# f28002x_erad_crc_global_regs register map
Vendor: Texas Instruments
Peripheral module from a debugger description file (folder C2000).
Address unit: 16 bits
Registers are 16-bit, read-write, no defined reset value unless marked. A register's access mark holds for its fields unless they carry their own. Offsets are as the file gives them; lines under a group give offsets from that group; [hi:lo] are bit positions; {n}, {i} and the like mark numbered series; 'fields as' and 'values as' point back to an identical list; <NAME> marks a mode.

## ERAD_CRC_GLOBAL_REGS — ERAD CRC GLOBAL Registers
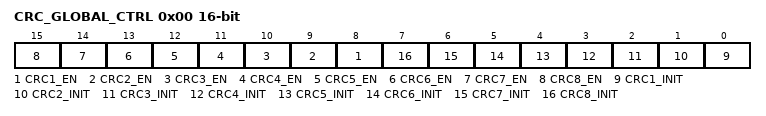
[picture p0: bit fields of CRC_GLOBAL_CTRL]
0x00 CRC_GLOBAL_CTRL — CRC_GLOBAL_CRTL
  [n+7] CRC{n}_EN (n=1..8) — Enable CRC Module {n}
  [n-1] CRC{n}_INIT (n=1..8) — Initialize CRC Module {n}
